VERSION ""

NS_ :

BS_:
BU_: battery
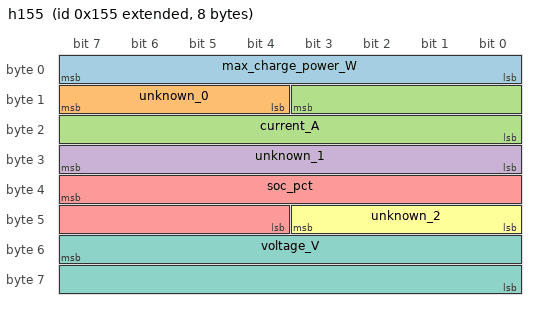
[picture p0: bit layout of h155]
BO_ 2147483989 h155: 8 battery
   SG_ max_charge_power_W : 7|8@0+ (300,0) [0|1] "W" bms
   SG_ unknown_0 : 15|4@0+ (1,0) [0|1] "" bms
   SG_ current_A : 11|12@0+ (0.25,-500) [0|1] "A" bms
   SG_ unknown_1 : 31|8@0+ (1,0) [0|1] "" bms
   SG_ soc_pct : 39|12@0+ (0.04,0) [0|1] "%" bms
   SG_ unknown_2 : 43|4@0+ (1,0) [0|1] "" bms
   SG_ voltage_V : 55|16@0+ (0.5,0) [0|1] "V" bms

BA_DEF_ BO_ "GenMsgBackgroundColor" STRING ;
BA_DEF_ BO_ "GenMsgForegroundColor" STRING ;
BA_DEF_ BO_ "filterlabeling" INT 0 0;
BA_DEF_DEF_ "GenMsgBackgroundColor" "#ffffff";
BA_DEF_DEF_ "GenMsgForegroundColor" "#000000";
BA_DEF_DEF_ "filterlabeling" 1;
VAL_ 2147483989 bms_voltage_V 0 "No Description";
